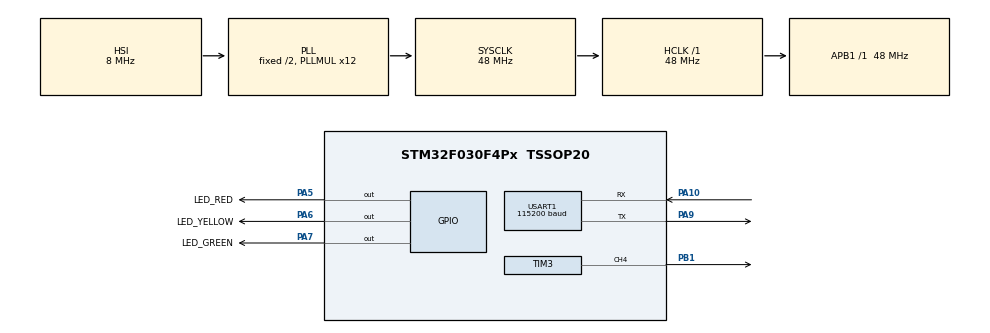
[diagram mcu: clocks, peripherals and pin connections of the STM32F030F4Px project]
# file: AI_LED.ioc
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Mcu.Family=STM32F0
Mcu.Name=STM32F030F4Px
Mcu.Package=TSSOP20
PA10.Mode=Asynchronous
PA10.Signal=USART1_RX
PA13.Mode=Serial_Wire
PA13.Signal=SYS_SWDIO
PA14.Mode=Serial_Wire
PA14.Signal=SYS_SWCLK
PA5.GPIO_Label=LED_RED
PA5.Signal=GPIO_Output
PA6.GPIO_Label=LED_YELLOW
PA6.Signal=GPIO_Output
PA7.GPIO_Label=LED_GREEN
PA7.Signal=GPIO_Output
PA9.Mode=Asynchronous
PA9.Signal=USART1_TX
PB1.Signal=S_TIM3_CH4
ProjectManager.HeapSize=0x200
ProjectManager.StackSize=0x400
ProjectManager.TargetToolchain=MDK-ARM V5.32
RCC.AHBFreq_Value=48000000
RCC.APB1Freq_Value=48000000
RCC.APB1TimFreq_Value=48000000
RCC.HCLKFreq_Value=48000000
RCC.PLLMUL=RCC_PLL_MUL12
RCC.SYSCLKFreq_VALUE=48000000
RCC.SYSCLKSource=RCC_SYSCLKSOURCE_PLLCLK
SH.S_TIM3_CH4.0=TIM3_CH4,PWM Generation4 CH4
TIM3.Channel-PWM\ Generation4\ CH4=TIM_CHANNEL_4
USART1.BaudRate=115200
USART1.VirtualMode-Asynchronous=VM_ASYNC
board=custom

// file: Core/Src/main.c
/* USER CODE BEGIN Header */
/**
  ******************************************************************************
  * @file           : main.c
  * @brief          : Main program body
  ******************************************************************************
  * @attention
  *
  * Copyright (c) 2026 STMicroelectronics.
  * All rights reserved.
  *
  * This software is licensed under terms that can be found in the LICENSE file
  * in the root directory of this software component.
  * If no LICENSE file comes with this software, it is provided AS-IS.
  *
  ******************************************************************************
  */
/* USER CODE END Header */
#include "main.h"
#include "tim.h"
#include "usart.h"
#include "gpio.h"

/* USER CODE BEGIN Includes */
#include "protocol.h"
#include "led.h"
#include "buzzer.h"
#include "storage.h"
/* USER CODE END Includes */

void SystemClock_Config(void);

int main(void)
{

  /* MCU Configuration--------------------------------------------------------*/

  /* Reset of all peripherals, Initializes the Flash interface and the Systick. */
  HAL_Init();

  /* Configure the system clock */
  SystemClock_Config();

  /* Initialize all configured peripherals */
  MX_GPIO_Init();
  MX_TIM3_Init();
  MX_USART1_UART_Init();
  /* USER CODE BEGIN 2 */

  /* 初始化Flash存储 (从Flash读取蜂鸣器配置，掉电保存) */
  Storage_Init();

  /* 初始化协议解析器 */
  Protocol_Init();

  /* 初始化蜂鸣器 (启动PWM) */
  Buzzer_Init();

  /* 上电自检: 所有指示灯亮0.5s + 蜂鸣器响0.5s */
  LED_AllOn();                      /* 点亮所有LED */
  Buzzer_BeepShort();               /* 蜂鸣器短响0.5s (复用绿灯提示音) */
  HAL_Delay(500);                   /* 持续500ms */
  LED_AllOff();                     /* 熄灭所有LED */
  /* 蜂鸣器会通过Buzzer_Process()在主循环中自动停止 */

  /* USER CODE END 2 */

  /* Infinite loop */
  while (1)
  {

    /* USER CODE BEGIN 3 */

    /* 处理协议帧 */
    Protocol_Process();

    /* 蜂鸣器定时关闭处理 */
    Buzzer_Process();

  }
  /* USER CODE END 3 */
}

void SystemClock_Config(void)
{
  RCC_OscInitTypeDef RCC_OscInitStruct = {0};
  RCC_ClkInitTypeDef RCC_ClkInitStruct = {0};
  RCC_PeriphCLKInitTypeDef PeriphClkInit = {0};

  /** Initializes the RCC Oscillators according to the specified parameters
  * in the RCC_OscInitTypeDef structure.
  */
  RCC_OscInitStruct.OscillatorType = RCC_OSCILLATORTYPE_HSI;
  RCC_OscInitStruct.HSIState = RCC_HSI_ON;
  RCC_OscInitStruct.HSICalibrationValue = RCC_HSICALIBRATION_DEFAULT;
  RCC_OscInitStruct.PLL.PLLState = RCC_PLL_ON;
  RCC_OscInitStruct.PLL.PLLSource = RCC_PLLSOURCE_HSI;
  RCC_OscInitStruct.PLL.PLLMUL = RCC_PLL_MUL12;
  RCC_OscInitStruct.PLL.PREDIV = RCC_PREDIV_DIV1;
  if (HAL_RCC_OscConfig(&RCC_OscInitStruct) != HAL_OK)
  {
    Error_Handler();
  }

  /** Initializes the CPU, AHB and APB buses clocks
  */
  RCC_ClkInitStruct.ClockType = RCC_CLOCKTYPE_HCLK|RCC_CLOCKTYPE_SYSCLK
                              |RCC_CLOCKTYPE_PCLK1;
  RCC_ClkInitStruct.SYSCLKSource = RCC_SYSCLKSOURCE_PLLCLK;
  RCC_ClkInitStruct.AHBCLKDivider = RCC_SYSCLK_DIV1;
  RCC_ClkInitStruct.APB1CLKDivider = RCC_HCLK_DIV1;

  if (HAL_RCC_ClockConfig(&RCC_ClkInitStruct, FLASH_LATENCY_1) != HAL_OK)
  {
    Error_Handler();
  }
  PeriphClkInit.PeriphClockSelection = RCC_PERIPHCLK_USART1;
  PeriphClkInit.Usart1ClockSelection = RCC_USART1CLKSOURCE_PCLK1;
  if (HAL_RCCEx_PeriphCLKConfig(&PeriphClkInit) != HAL_OK)
  {
    Error_Handler();
  }
}

void Error_Handler(void)
{
  __disable_irq();
  while (1)
  {
  }
}
